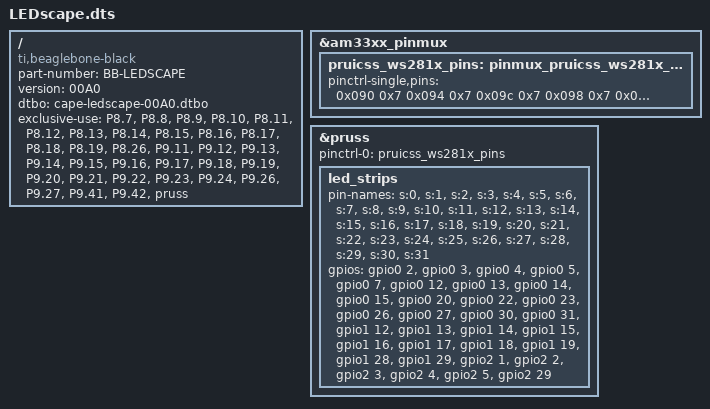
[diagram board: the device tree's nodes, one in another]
/** \file
 * Try to play nice with the Beagle Bone device tree.
 *
 * But it really sucks.  This is a waste of time; we can just use
 * a shell script to poke the gpio export and config files since this
 * is so borked.
 */
/dts-v1/;
/plugin/;

/ {
    compatible = "ti,beaglebone-black";

    /* identification */
    part-number = "BB-LEDSCAPE";
    version = "00A0";
    dtbo = "cape-ledscape-00A0.dtbo";

    /* state the resources this cape uses or prepare to get winged! */
    exclusive-use =
        /* 32 IO pins for the PRU to use */
        "P8.7",  "P8.8",
	"P8.9",  "P8.10",
	"P8.11", "P8.12",
	"P8.13", "P8.14",
	"P8.15", "P8.16",
	"P8.17", "P8.18",
	"P8.19",
	          "P8.26",

	"P9.11", "P9.12",
	"P9.13", "P9.14",
	"P9.15", "P9.16",
	"P9.17", "P9.18",
	"P9.19", "P9.20", // overrides the i2c bus
	"P9.21", "P9.22",
	"P9.23", "P9.24",
	         "P9.26",
	"P9.27",
	"P9.41", "P9.42",

	// And we need the PRU
        "pruss"; 

    fragment@0 {
        target = <&am33xx_pinmux>;
        __overlay__ {
            pruicss_ws281x_pins: pinmux_pruicss_ws281x_pins {
		// Mode 7 is GPIO output
		// GPIO0: 2 3 4 5 7 12 13 14 15 20 22 23 26 27 30 31
                pinctrl-single,pins = <
			0x090 0x7 /* P8.7 gpio2.2 */
			0x094 0x7 // P8.8 gpio2.3
			0x09c 0x7 // P8.9 gpio2.5
			0x098 0x7 // P8.10 gpio 2.4
			0x034 0x7 // P8.11 gpio1.13
			0x030 0x7 // P8.12 gpio1.12
			0x024 0x7 // P8.13 gpio0.23
			0x028 0x7 // P8.14 gpio0.26
			0x03c 0x7 // P8.15 gpio1.15
			0x038 0x7 // P8.16 gpio1.14
			0x02c 0x7 // P8.17 gpio0.27
			0x08c 0x7 // P8.18 gpio2.1
			0x020 0x7 // P8.19 gpio0.22
			0x07c 0x7 // P8.26 gpio1.29

			0x070 0x7 // P9.11 gpio0.30
			0x078 0x7 // P9.12 gpio1.28
			0x074 0x7 // P9.13 gpio0.31
			0x048 0x7 // P9.14 gpio1.18
			0x040 0x7 // P9.15 gpio1.16
			0x04c 0x7 // P9.16 gpio1.19
			0x15c 0x7 // P9.17 gpio0.5
			0x158 0x7 // P9.18 gpio0.4
			0x17e 0x7 // P9.19 gpio0.13, overrides i2c
			0x178 0x7 // P9.20 gpio0.12, overrides i2c
			0x154 0x7 // P9.21 gpio0.3
			0x150 0x7 // P9.22 gpio0.2
			0x044 0x7 // P9.23 gpio1.17
			0x184 0x7 // P9.24 gpio0.15
			0x180 0x7 // P9.26 gpio0.14
			//0x1a4 0x7 // P9.27 gpio3.19
			//0x198 0x7 // P9.30 gpio3.16
			0x1b4 0x7 // P9.41 gpio0.20
			0x164 0x7 // P9.42 gpio0.7
                >;
            };
        };
    };

/*
 fragment@1 {
    target = <&ocp>;
    __overlay__ {
      ws281x_pinmux_helper: helper {
        compatible = "bone-pinmux-helper";
        pinctrl-names = "default";
        pinctrl-0 = <&pinctrl_ws281x>;
        status = "okay";
      };
    };
  };
*/

    fragment@1{
        target = <&pruss>;
        __overlay__{
            status = "okay";
        pinctrl-names = "default";
        pinctrl-0 = <&pruicss_ws281x_pins>;
	    led_strips {
                pin-names     =
			"s:0",
			"s:1",
			"s:2",
			"s:3",
			"s:4",
			"s:5",
			"s:6",
			"s:7",
			"s:8",
			"s:9",
			"s:10",
			"s:11",
			"s:12",
			"s:13",
			"s:14",
			"s:15",
			"s:16",
			"s:17",
			"s:18",
			"s:19",
			"s:20",
			"s:21",
			"s:22",
			"s:23",
			"s:24",
			"s:25",
			"s:26",
			"s:27",
			"s:28",
			"s:29",
			"s:30",
			"s:31";

                gpios         = <
&gpio0 2 0
&gpio0 3 0
&gpio0 4 0
&gpio0 5 0
&gpio0 7 0
&gpio0 12 0
&gpio0 13 0
&gpio0 14 0
&gpio0 15 0
&gpio0 20 0
&gpio0 22 0
&gpio0 23 0
&gpio0 26 0
&gpio0 27 0
&gpio0 30 0
&gpio0 31 0
&gpio1 12 0
&gpio1 13 0
&gpio1 14 0
&gpio1 15 0
&gpio1 16 0
&gpio1 17 0
&gpio1 18 0
&gpio1 19 0
&gpio1 28 0
&gpio1 29 0
&gpio2 1 0
&gpio2 2 0
&gpio2 3 0
&gpio2 4 0
&gpio2 5 0
&gpio2 29 0
//&gpio3 16 0
//&gpio3 19 0
		>; 
            };            
        };
    };
};
